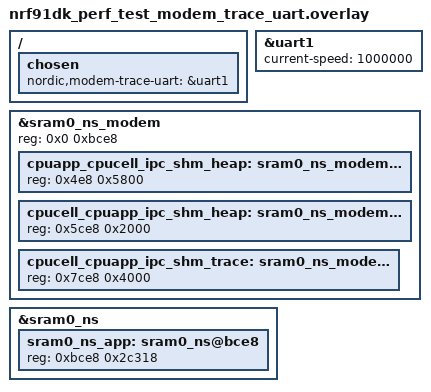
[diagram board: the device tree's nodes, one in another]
/*
 * Copyright (c) 2026 Nordic Semiconductor ASA
 *
 * SPDX-License-Identifier: LicenseRef-Nordic-5-Clause
 */

/* Enable uart1 for tracing. */
&uart1 {
	status = "okay";
	current-speed = <1000000>;
};

/ {
	chosen {
		nordic,modem-trace-uart = &uart1;
	};
};

/delete-node/ &cpuapp_cpucell_ipc_shm_heap;
/delete-node/ &cpucell_cpuapp_ipc_shm_heap;

/* Increase modem (shared) memory, bump TX buffer size to 22 kB and add trace buffer. */
&sram0_ns_modem {
	reg = <0x0 0xbce8>;
	ranges = <0x0 0x0 0xbce8>;

	cpuapp_cpucell_ipc_shm_heap: sram0_ns_modem@4e8 {
		/* Modem IPC transmit */
		reg = <0x4e8 0x5800>;
	};

	cpucell_cpuapp_ipc_shm_heap: sram0_ns_modem@5ce8 {
		/* Modem IPC receive */
		reg = <0x5ce8 0x2000>;
	};

	cpucell_cpuapp_ipc_shm_trace: sram0_ns_modem@7ce8 {
		/* Modem trace memory */
		reg = <0x7ce8 0x4000>;
	};
};

/* Delete Non-Secure application memory so we can move and shrink it. */
/delete-node/ &sram0_ns_app;

&sram0_ns {
	sram0_ns_app: sram0_ns@bce8 {
		/* Redefine smaller Non-Secure application memory. */
		reg = <0xbce8 0x2c318>;
	};
};
